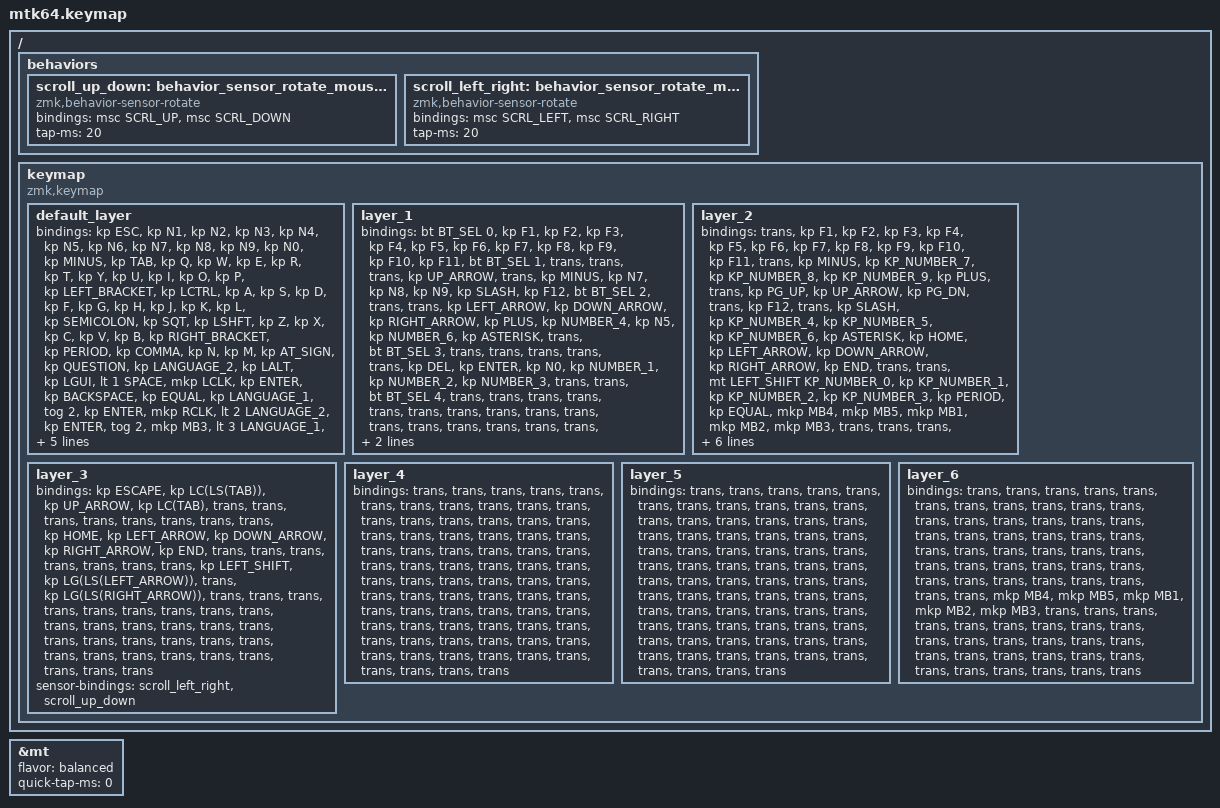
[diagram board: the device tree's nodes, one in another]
#include <behaviors.dtsi>
#include <dt-bindings/zmk/bt.h>
#include <dt-bindings/zmk/keys.h>
#include <dt-bindings/zmk/pointing.h>
#include "keycode_japanese.h"

// スクロール量の設定

#define ZMK_POINTING_DEFAULT_SCRL_VAL 100

&mt {
    flavor = "balanced";
    quick-tap-ms = <0>;
};

/ {
    behaviors {
        // 垂直スクロール用のbehaviorの設定

        scroll_up_down: behavior_sensor_rotate_mouse_wheel_up_down {
            compatible = "zmk,behavior-sensor-rotate";
            #sensor-binding-cells = <0>;
            bindings = <&msc SCRL_UP>, <&msc SCRL_DOWN>;

            tap-ms = <20>; // スクロールのタップ時間
        };

        // 水平スクロール用のbehaviorの設定

        scroll_left_right: behavior_sensor_rotate_mouse_wheel_left_right {
            compatible = "zmk,behavior-sensor-rotate";
            #sensor-binding-cells = <0>;
            bindings = <&msc SCRL_LEFT>, <&msc SCRL_RIGHT>;

            tap-ms = <20>; // スクロールのタップ時間
        };
    };
};

/ {
    keymap {
        compatible = "zmk,keymap";

        default_layer {
            bindings = <
&kp ESC  &kp N1  &kp N2  &kp N3  &kp N4  &kp N5  &kp N6  &kp N7  &kp N8  &kp N9  &kp N0  &kp MINUS  &kp TAB  &kp Q  &kp W  &kp E  &kp R  &kp T  &kp Y  &kp U  &kp I  &kp O  &kp P  &kp LEFT_BRACKET  &kp LCTRL  &kp A  &kp S  &kp D  &kp F  &kp G  &kp H  &kp J  &kp K  &kp L  &kp SEMICOLON  &kp SQT  &kp LSHFT  &kp Z  &kp X  &kp C  &kp V  &kp B  &kp RIGHT_BRACKET  &kp PERIOD  &kp COMMA  &kp N  &kp M  &kp AT_SIGN  &kp QUESTION  &kp LANGUAGE_2  &kp LALT  &kp LGUI  &lt 1 SPACE  &mkp LCLK  &kp ENTER  &kp BACKSPACE  &kp EQUAL  &kp LANGUAGE_1  &tog 2  &kp ENTER  &mkp RCLK  &lt 2 LANGUAGE_2  &kp ENTER  &tog 2  &mkp MB3  &lt 3 LANGUAGE_1  &mo 1  &mo 2  &mo 3  &mo 1  &mo 2  &mo 3  &mo 1  &mo 2  &mo 3
            >;

            sensor-bindings = <
                &inc_dec_kp LEFT_ARROW RIGHT_ARROW
                &inc_dec_kp UP_ARROW   DOWN_ARROW
            >;
        };

        layer_1 {
            bindings = <
&bt BT_SEL 0  &kp F1  &kp F2  &kp F3  &kp F4  &kp F5  &kp F6  &kp F7  &kp F8  &kp F9  &kp F10  &kp F11  &bt BT_SEL 1  &trans  &trans  &trans  &kp UP_ARROW  &trans  &kp MINUS  &kp N7  &kp N8  &kp N9  &kp SLASH  &kp F12  &bt BT_SEL 2  &trans  &trans  &kp LEFT_ARROW  &kp DOWN_ARROW  &kp RIGHT_ARROW  &kp PLUS  &kp NUMBER_4  &kp N5  &kp NUMBER_6  &kp ASTERISK  &trans  &bt BT_SEL 3  &trans  &trans  &trans  &trans  &trans  &kp DEL  &kp ENTER  &kp N0  &kp NUMBER_1  &kp NUMBER_2  &kp NUMBER_3  &trans  &trans  &bt BT_SEL 4  &trans  &trans  &trans  &trans  &trans  &trans  &trans  &trans  &trans  &trans  &trans  &trans  &trans  &trans  &trans  &trans  &trans  &trans  &trans  &trans  &trans  &trans  &trans  &trans
            >;
        };

        layer_2 {
            bindings = <
&trans  &kp F1  &kp F2  &kp F3  &kp F4  &kp F5  &kp F6  &kp F7  &kp F8  &kp F9  &kp F10  &kp F11  &trans  &kp MINUS  &kp KP_NUMBER_7  &kp KP_NUMBER_8  &kp KP_NUMBER_9  &kp PLUS  &trans  &kp PG_UP  &kp UP_ARROW  &kp PG_DN  &trans  &kp F12  &trans  &kp SLASH  &kp KP_NUMBER_4  &kp KP_NUMBER_5  &kp KP_NUMBER_6  &kp ASTERISK  &kp HOME  &kp LEFT_ARROW  &kp DOWN_ARROW  &kp RIGHT_ARROW  &kp END  &trans  &trans  &mt LEFT_SHIFT KP_NUMBER_0  &kp KP_NUMBER_1  &kp KP_NUMBER_2  &kp KP_NUMBER_3  &kp PERIOD  &kp EQUAL  &mkp MB4  &mkp MB5  &mkp MB1  &mkp MB2  &mkp MB3  &trans  &trans  &trans  &trans  &trans  &trans  &trans  &trans  &trans  &trans  &trans  &trans  &trans  &trans  &trans  &trans  &trans  &trans  &trans  &trans  &trans  &trans  &trans  &trans  &trans  &trans  &trans
            >;

            sensor-bindings = <
                &inc_dec_kp TAB LC(TAB) 
                &inc_dec_kp PG_UP PG_DN
            >;
        };

        layer_3 {
            bindings = <
&kp ESCAPE  &kp LC(LS(TAB))  &kp UP_ARROW  &kp LC(TAB)  &trans  &trans  &trans  &trans  &trans  &trans  &trans  &trans  &kp HOME  &kp LEFT_ARROW  &kp DOWN_ARROW  &kp RIGHT_ARROW  &kp END  &trans  &trans  &trans  &trans  &trans  &trans  &trans  &kp LEFT_SHIFT  &kp LG(LS(LEFT_ARROW))  &trans  &kp LG(LS(RIGHT_ARROW))  &trans  &trans  &trans  &trans  &trans  &trans  &trans  &trans  &trans  &trans  &trans  &trans  &trans  &trans  &trans  &trans  &trans  &trans  &trans  &trans  &trans  &trans  &trans  &trans  &trans  &trans  &trans  &trans  &trans  &trans
            >;

            sensor-bindings = <
                &scroll_left_right
                &scroll_up_down
            >;
        };

        layer_4 {
            bindings = <
&trans  &trans  &trans  &trans  &trans  &trans  &trans  &trans  &trans  &trans  &trans  &trans  &trans  &trans  &trans  &trans  &trans  &trans  &trans  &trans  &trans  &trans  &trans  &trans  &trans  &trans  &trans  &trans  &trans  &trans  &trans  &trans  &trans  &trans  &trans  &trans  &trans  &trans  &trans  &trans  &trans  &trans  &trans  &trans  &trans  &trans  &trans  &trans  &trans  &trans  &trans  &trans  &trans  &trans  &trans  &trans  &trans  &trans  &trans  &trans  &trans  &trans  &trans  &trans  &trans  &trans  &trans  &trans  &trans  &trans  &trans  &trans  &trans  &trans  &trans
            >;
        };

        layer_5 {
            bindings = <
&trans  &trans  &trans  &trans  &trans  &trans  &trans  &trans  &trans  &trans  &trans  &trans  &trans  &trans  &trans  &trans  &trans  &trans  &trans  &trans  &trans  &trans  &trans  &trans  &trans  &trans  &trans  &trans  &trans  &trans  &trans  &trans  &trans  &trans  &trans  &trans  &trans  &trans  &trans  &trans  &trans  &trans  &trans  &trans  &trans  &trans  &trans  &trans  &trans  &trans  &trans  &trans  &trans  &trans  &trans  &trans  &trans  &trans  &trans  &trans  &trans  &trans  &trans  &trans  &trans  &trans  &trans  &trans  &trans  &trans  &trans  &trans  &trans  &trans  &trans
            >;
        };

        layer_6 {
            bindings = <
&trans  &trans  &trans  &trans  &trans  &trans  &trans  &trans  &trans  &trans  &trans  &trans  &trans  &trans  &trans  &trans  &trans  &trans  &trans  &trans  &trans  &trans  &trans  &trans  &trans  &trans  &trans  &trans  &trans  &trans  &trans  &trans  &trans  &trans  &trans  &trans  &trans  &trans  &trans  &trans  &trans  &trans  &trans  &mkp MB4  &mkp MB5  &mkp MB1  &mkp MB2  &mkp MB3  &trans  &trans  &trans  &trans  &trans  &trans  &trans  &trans  &trans  &trans  &trans  &trans  &trans  &trans  &trans  &trans  &trans  &trans  &trans  &trans  &trans  &trans  &trans  &trans  &trans  &trans  &trans
            >;
        };
    };
};
